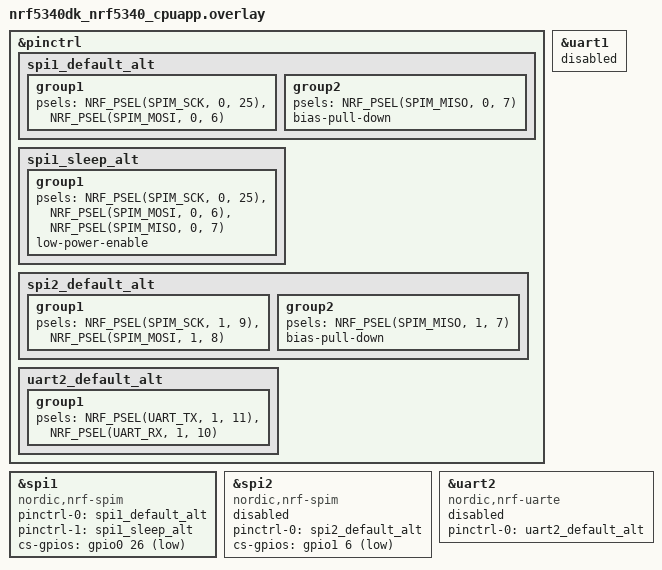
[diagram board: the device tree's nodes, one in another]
&pinctrl {
	spi1_default_alt: spi1_default_alt {
		group1 {
			psels = <NRF_PSEL(SPIM_SCK, 0, 25)>,
				<NRF_PSEL(SPIM_MOSI, 0, 6)>;
		};
		group2 {
			psels = <NRF_PSEL(SPIM_MISO, 0, 7)>;
			bias-pull-down;
		};
	};

	spi1_sleep_alt: spi1_sleep_alt {
		group1 {
			psels = <NRF_PSEL(SPIM_SCK, 0, 25)>,
				<NRF_PSEL(SPIM_MOSI, 0, 6)>,
				<NRF_PSEL(SPIM_MISO, 0, 7)>;
			low-power-enable;
		};
	};

	spi2_default_alt: spi2_default_alt {
		group1 {
			psels = <NRF_PSEL(SPIM_SCK, 1, 9)>,
				<NRF_PSEL(SPIM_MOSI, 1, 8)>;
		};
		group2 {
			psels =	<NRF_PSEL(SPIM_MISO, 1, 7)>;
			bias-pull-down;
		};
	};

	uart2_default_alt: uart2_default_alt {
		group1 {
			psels = <NRF_PSEL(UART_TX, 1, 11)>,
				<NRF_PSEL(UART_RX, 1, 10)>;
		};
	};
};

/* This node corresponds to the SPIM1 peripheral that is to be used via
 * the Zephyr driver, so it must have the status set to "okay".
 */
&spi1 {
	compatible = "nordic,nrf-spim";
	status = "okay";
	pinctrl-0 = <&spi1_default_alt>;
	pinctrl-1 = <&spi1_sleep_alt>;
	pinctrl-names = "default", "sleep";
	cs-gpios = <&gpio0 26 GPIO_ACTIVE_LOW>;
};

/* The UARTE1 peripheral share the same ID with SPIM1, hence these two
 * peripherals cannot be used simultaneously and this node must be disabled.
 */
&uart1 {
	status = "disabled";
};

/* The following two nodes (corresponding to the SPIM2 and UARTE2 peripherals,
 * respectively) need to be disabled so that Zephyr drivers won't initialize
 * those instances; the application will use them via nrfx drivers. But their
 * pins must be specified, as the application expects to get this information
 * from devicetree.
 */
&spi2 {
	compatible = "nordic,nrf-spim";
	status = "disabled";
	pinctrl-0 = <&spi2_default_alt>;
	/delete-property/ pinctrl-1;
	pinctrl-names = "default";
	cs-gpios = <&gpio1 6 GPIO_ACTIVE_LOW>;
};

&uart2 {
	compatible = "nordic,nrf-uarte";
	status = "disabled";
	pinctrl-0 = <&uart2_default_alt>;
	pinctrl-names = "default";
};
